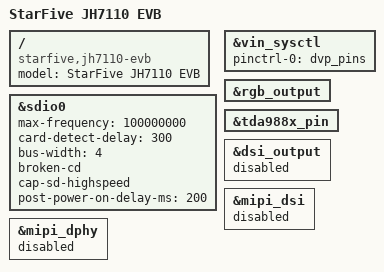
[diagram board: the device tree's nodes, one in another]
// SPDX-License-Identifier: GPL-2.0 OR MIT
/*
 * Copyright (C) 2022 StarFive Technology Co., Ltd.
 * Copyright (C) 2022 Hal Feng <hal.feng@starfivetech.com>
 */

/dts-v1/;
#include "jh7110-evb.dtsi"

/ {
	model = "StarFive JH7110 EVB";
	compatible = "starfive,jh7110-evb", "starfive,jh7110";
};

/* default sd card */
&sdio0 {
	max-frequency = <100000000>;
	card-detect-delay = <300>;
	bus-width = <4>;
	broken-cd;
	cap-sd-highspeed;
	post-power-on-delay-ms = <200>;
	status = "okay";
};

&vin_sysctl {
	pinctrl-names = "default";
	pinctrl-0 = <&dvp_pins>;
};

&rgb_output {
	status = "okay";
};

&tda988x_pin {
	status = "okay";
};

&dsi_output {
	status = "disabled";
};

&mipi_dsi {
	status = "disabled";
};

&mipi_dphy {
	status = "disabled";
};
